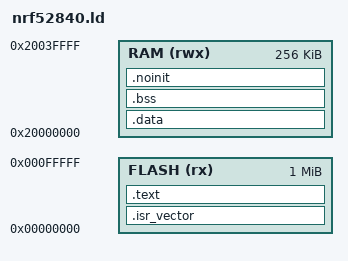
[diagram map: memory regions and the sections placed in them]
ENTRY(Reset_Handler)

MEMORY
{
    FLASH (rx)  : ORIGIN = 0x00000000, LENGTH = 1024K
    RAM   (rwx) : ORIGIN = 0x20000000, LENGTH = 256K
}

_stack_top = ORIGIN(RAM) + LENGTH(RAM);

SECTIONS
{
    .isr_vector :
    {
        . = ALIGN(4);
        KEEP(*(.isr_vector))
        . = ALIGN(4);
    } > FLASH

    .text :
    {
        . = ALIGN(4);
        *(.text*)
        *(.rodata*)
        KEEP(*(.init))
        KEEP(*(.fini))
        . = ALIGN(4);
        _etext = .;
    } > FLASH

    .data : AT(_etext)
    {
        . = ALIGN(4);
        _sdata = .;
        *(.data*)
        . = ALIGN(4);
        _edata = .;
    } > RAM

    .bss (NOLOAD) :
    {
        . = ALIGN(4);
        _sbss = .;
        *(.bss*)
        *(COMMON)
        . = ALIGN(4);
        _ebss = .;
    } > RAM

    .noinit (NOLOAD) :
    {
        . = ALIGN(4);
        *(.noinit*)
        . = ALIGN(4);
    } > RAM

    /DISCARD/ :
    {
        *(.note*)
        *(.comment*)
    }
}

ASSERT(_etext + SIZEOF(.data) <= ORIGIN(FLASH) + LENGTH(FLASH),
       "FLASH overflow")
ASSERT(_ebss <= ORIGIN(RAM) + LENGTH(RAM), "RAM overflow")

